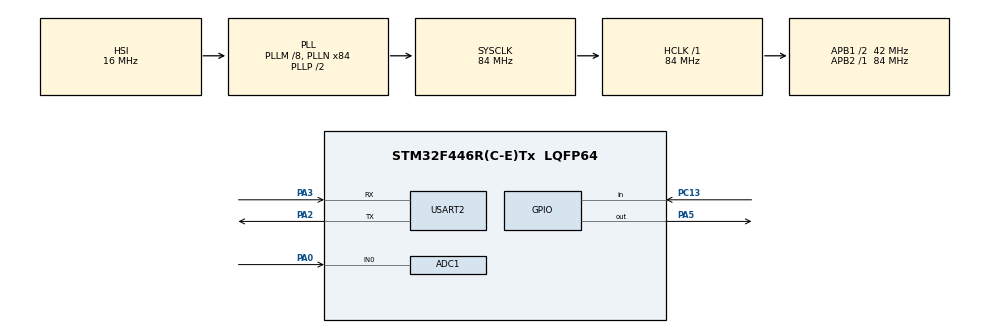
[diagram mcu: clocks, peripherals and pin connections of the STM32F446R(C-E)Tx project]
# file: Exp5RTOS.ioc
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ADC1.Channel-0\#ChannelRegularConversion=ADC_CHANNEL_0
ADC1.NbrOfConversionFlag=1
ADC1.Rank-0\#ChannelRegularConversion=1
ADC1.SamplingTime-0\#ChannelRegularConversion=ADC_SAMPLETIME_3CYCLES
ADC1.master=1
Mcu.Family=STM32F4
Mcu.Name=STM32F446R(C-E)Tx
Mcu.Package=LQFP64
NVIC.PriorityGroup=NVIC_PRIORITYGROUP_4
PA0-WKUP.Signal=ADCx_IN0
PA2.Mode=Asynchronous
PA2.Signal=USART2_TX
PA3.Mode=Asynchronous
PA3.Signal=USART2_RX
PA5.Signal=GPIO_Output
PC13.Signal=GPIO_Input
PC14-OSC32_IN.Mode=LSE-External-Clock-Source
PC14-OSC32_IN.Signal=RCC_OSC32_IN
PC15-OSC32_OUT.Mode=LSE-External-Clock-Source
PC15-OSC32_OUT.Signal=RCC_OSC32_OUT
PH0-OSC_IN.Mode=HSE-External-Clock-Source
PH0-OSC_IN.Signal=RCC_OSC_IN
PH1-OSC_OUT.Mode=HSE-External-Clock-Source
PH1-OSC_OUT.Signal=RCC_OSC_OUT
ProjectManager.HeapSize=0x200
ProjectManager.StackSize=0x400
ProjectManager.TargetToolchain=STM32CubeIDE
RCC.AHBFreq_Value=84000000
RCC.APB1CLKDivider=RCC_HCLK_DIV2
RCC.APB1Freq_Value=42000000
RCC.APB1TimFreq_Value=84000000
RCC.APB2Freq_Value=84000000
RCC.APB2TimFreq_Value=84000000
RCC.CortexFreq_Value=84000000
RCC.HCLKFreq_Value=84000000
RCC.PLLM=8
RCC.PLLN=84
RCC.SYSCLKFreq_VALUE=84000000
RCC.SYSCLKSource=RCC_SYSCLKSOURCE_PLLCLK
RCC.USBFreq_Value=84000000
RCC.VCOOutputFreq_Value=168000000
SH.ADCx_IN0.0=ADC1_IN0,IN0
USART2.VirtualMode=VM_ASYNC
board=custom

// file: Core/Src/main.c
/* USER CODE BEGIN Header */
/**
  ******************************************************************************
  * @file           : main.c
  * @brief          : Main program body
  ******************************************************************************
  */
 /* USER CODE END Header */

#include "main.h"
#include <stdio.h>
#include <string.h>

ADC_HandleTypeDef hadc1;
UART_HandleTypeDef huart2;

/* USER CODE BEGIN PV */
volatile uint32_t led_counter_ms    = 0;
volatile uint32_t button_counter_ms = 0;
volatile uint32_t ir_counter_ms     = 0;
volatile uint32_t last_time_ms      = 0;

volatile uint8_t  button_pressed = 0;
volatile uint16_t ir_value = 0;

char uart_buf[64];
/* USER CODE END PV */

void SystemClock_Config(void);
static void MX_GPIO_Init(void);
static void MX_ADC1_Init(void);
static void MX_USART2_UART_Init(void);

/* USER CODE BEGIN 0 */
static inline uint32_t GetTimeMs(void)
{
    return HAL_GetTick();   // 1 ms system tick
}
/* USER CODE END 0 */

int main(void)
{
  HAL_Init();
  SystemClock_Config();

  MX_GPIO_Init();
  MX_ADC1_Init();
  MX_USART2_UART_Init();

  last_time_ms = GetTimeMs();

  while (1)
  {
    uint32_t now_ms = GetTimeMs();
    uint32_t dt = now_ms - last_time_ms;
    last_time_ms = now_ms;

    led_counter_ms    += dt;
    button_counter_ms += dt;
    ir_counter_ms     += dt;

    /* ---------- LED Blink (500 ms) ---------- */
    if (led_counter_ms >= 500)
    {
      led_counter_ms = 0;
      HAL_GPIO_TogglePin(GPIOA, GPIO_PIN_5);
    }

    /* ---------- Button Read (50 ms) ---------- */
    if (button_counter_ms >= 50)
    {
      button_counter_ms = 0;

      if (HAL_GPIO_ReadPin(GPIOC, GPIO_PIN_13) == GPIO_PIN_RESET)
      {
        button_pressed = 1;
        HAL_GPIO_WritePin(GPIOA, GPIO_PIN_5, GPIO_PIN_SET);
      }
      else
      {
        button_pressed = 0;
      }
    }

    /* ---------- IR Sensor + UART (200 ms) ---------- */
    if (ir_counter_ms >= 200)
    {
      ir_counter_ms = 0;

      HAL_ADC_Start(&hadc1);
      HAL_ADC_PollForConversion(&hadc1, 10);

      if (HAL_ADC_GetState(&hadc1) & HAL_ADC_STATE_REG_EOC)
      {
        ir_value = HAL_ADC_GetValue(&hadc1);

        int len = sprintf(uart_buf,
            "IR: %d | Button: %s\r\n",
            ir_value,
            button_pressed ? "PRESSED" : "RELEASED");

        HAL_UART_Transmit(&huart2,
                          (uint8_t *)uart_buf,
                          len,
                          100);
      }

      HAL_ADC_Stop(&hadc1);
    }
  }
}

/* ---------------- SYSTEM CLOCK ---------------- */
void SystemClock_Config(void)
{
  RCC_OscInitTypeDef RCC_OscInitStruct = {0};
  RCC_ClkInitTypeDef RCC_ClkInitStruct = {0};

  __HAL_RCC_PWR_CLK_ENABLE();
  __HAL_PWR_VOLTAGESCALING_CONFIG(PWR_REGULATOR_VOLTAGE_SCALE3);

  RCC_OscInitStruct.OscillatorType = RCC_OSCILLATORTYPE_HSI;
  RCC_OscInitStruct.HSIState = RCC_HSI_ON;
  RCC_OscInitStruct.HSICalibrationValue = RCC_HSICALIBRATION_DEFAULT;
  RCC_OscInitStruct.PLL.PLLState = RCC_PLL_ON;
  RCC_OscInitStruct.PLL.PLLSource = RCC_PLLSOURCE_HSI;
  RCC_OscInitStruct.PLL.PLLM = 8;
  RCC_OscInitStruct.PLL.PLLN = 84;
  RCC_OscInitStruct.PLL.PLLP = RCC_PLLP_DIV2;
  RCC_OscInitStruct.PLL.PLLQ = 2;
  RCC_OscInitStruct.PLL.PLLR = 2;
  HAL_RCC_OscConfig(&RCC_OscInitStruct);

  RCC_ClkInitStruct.ClockType = RCC_CLOCKTYPE_SYSCLK |
                               RCC_CLOCKTYPE_HCLK |
                               RCC_CLOCKTYPE_PCLK1 |
                               RCC_CLOCKTYPE_PCLK2;
  RCC_ClkInitStruct.SYSCLKSource = RCC_SYSCLKSOURCE_PLLCLK;
  RCC_ClkInitStruct.AHBCLKDivider = RCC_SYSCLK_DIV1;
  RCC_ClkInitStruct.APB1CLKDivider = RCC_HCLK_DIV2;
  RCC_ClkInitStruct.APB2CLKDivider = RCC_HCLK_DIV1;
  HAL_RCC_ClockConfig(&RCC_ClkInitStruct, FLASH_LATENCY_2);
}

/* ---------------- ADC ---------------- */
static void MX_ADC1_Init(void)
{
  ADC_ChannelConfTypeDef sConfig = {0};

  hadc1.Instance = ADC1;
  hadc1.Init.ClockPrescaler = ADC_CLOCK_SYNC_PCLK_DIV4;
  hadc1.Init.Resolution = ADC_RESOLUTION_12B;
  hadc1.Init.ScanConvMode = DISABLE;
  hadc1.Init.ContinuousConvMode = DISABLE;
  hadc1.Init.ExternalTrigConv = ADC_SOFTWARE_START;
  hadc1.Init.DataAlign = ADC_DATAALIGN_RIGHT;
  hadc1.Init.NbrOfConversion = 1;
  HAL_ADC_Init(&hadc1);

  sConfig.Channel = ADC_CHANNEL_0;
  sConfig.Rank = 1;
  sConfig.SamplingTime = ADC_SAMPLETIME_3CYCLES;
  HAL_ADC_ConfigChannel(&hadc1, &sConfig);
}

/* ---------------- USART2 ---------------- */
static void MX_USART2_UART_Init(void)
{
  huart2.Instance = USART2;
  huart2.Init.BaudRate = 115200;
  huart2.Init.WordLength = UART_WORDLENGTH_8B;
  huart2.Init.StopBits = UART_STOPBITS_1;
  huart2.Init.Parity = UART_PARITY_NONE;
  huart2.Init.Mode = UART_MODE_TX_RX;
  huart2.Init.HwFlowCtl = UART_HWCONTROL_NONE;
  huart2.Init.OverSampling = UART_OVERSAMPLING_16;
  HAL_UART_Init(&huart2);
}

/* ---------------- GPIO ---------------- */
static void MX_GPIO_Init(void)
{
  GPIO_InitTypeDef GPIO_InitStruct = {0};

  __HAL_RCC_GPIOC_CLK_ENABLE();
  __HAL_RCC_GPIOA_CLK_ENABLE();

  /* PC13 -> Button */
  GPIO_InitStruct.Pin = GPIO_PIN_13;
  GPIO_InitStruct.Mode = GPIO_MODE_INPUT;
  GPIO_InitStruct.Pull = GPIO_NOPULL;
  HAL_GPIO_Init(GPIOC, &GPIO_InitStruct);

  /* PA5 -> LED */
  GPIO_InitStruct.Pin = GPIO_PIN_5;
  GPIO_InitStruct.Mode = GPIO_MODE_OUTPUT_PP;
  GPIO_InitStruct.Pull = GPIO_NOPULL;
  GPIO_InitStruct.Speed = GPIO_SPEED_FREQ_LOW;
  HAL_GPIO_Init(GPIOA, &GPIO_InitStruct);

  /* PA2 (TX) & PA3 (RX) -> USART2 */
  GPIO_InitStruct.Pin = GPIO_PIN_2 | GPIO_PIN_3;
  GPIO_InitStruct.Mode = GPIO_MODE_AF_PP;
  GPIO_InitStruct.Pull = GPIO_NOPULL;
  GPIO_InitStruct.Speed = GPIO_SPEED_FREQ_VERY_HIGH;
  GPIO_InitStruct.Alternate = GPIO_AF7_USART2;
  HAL_GPIO_Init(GPIOA, &GPIO_InitStruct);
}
